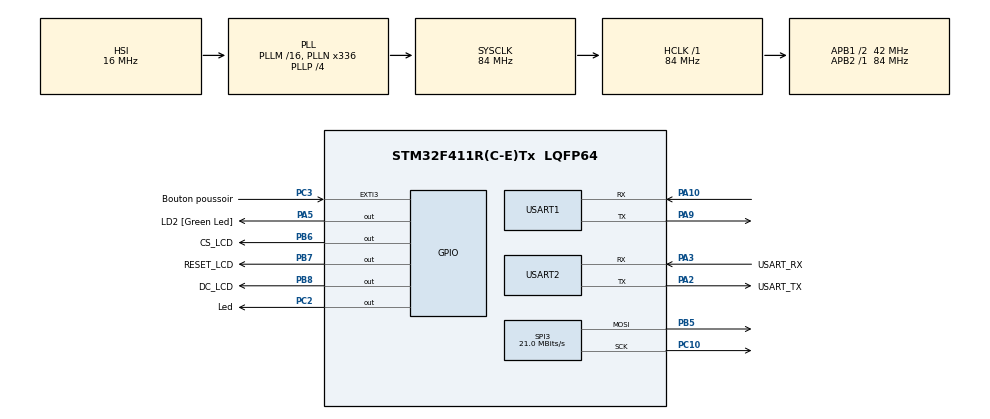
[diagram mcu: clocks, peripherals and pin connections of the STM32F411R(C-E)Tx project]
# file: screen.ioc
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Dma.Request0=SPI3_TX
Dma.SPI3_TX.0.Direction=DMA_MEMORY_TO_PERIPH
Dma.SPI3_TX.0.FIFOMode=DMA_FIFOMODE_DISABLE
Dma.SPI3_TX.0.Instance=DMA1_Stream5
Dma.SPI3_TX.0.MemDataAlignment=DMA_MDATAALIGN_BYTE
Dma.SPI3_TX.0.MemInc=DMA_MINC_ENABLE
Dma.SPI3_TX.0.Mode=DMA_NORMAL
Dma.SPI3_TX.0.PeriphDataAlignment=DMA_PDATAALIGN_BYTE
Dma.SPI3_TX.0.PeriphInc=DMA_PINC_DISABLE
Dma.SPI3_TX.0.Priority=DMA_PRIORITY_HIGH
Mcu.Family=STM32F4
Mcu.Name=STM32F411R(C-E)Tx
Mcu.Package=LQFP64
NVIC.DMA1_Stream5_IRQn=true\:0\:0\:false\:false\:true\:false\:true\:true
NVIC.EXTI3_IRQn=true\:0\:0\:false\:false\:true\:true\:true\:true
NVIC.PriorityGroup=NVIC_PRIORITYGROUP_0
PA10.Mode=Asynchronous
PA10.Signal=USART1_RX
PA13.GPIO_Label=TMS
PA13.Mode=Serial_Wire
PA13.Signal=SYS_JTMS-SWDIO
PA14.GPIO_Label=TCK
PA14.Mode=Serial_Wire
PA14.Signal=SYS_JTCK-SWCLK
PA2.GPIO_Label=USART_TX
PA2.Mode=Asynchronous
PA2.Signal=USART2_TX
PA3.GPIO_Label=USART_RX
PA3.Mode=Asynchronous
PA3.Signal=USART2_RX
PA5.GPIO_Label=LD2 [Green Led]
PA5.Signal=GPIO_Output
PA9.Mode=Asynchronous
PA9.Signal=USART1_TX
PB3.GPIO_Label=SWO
PB3.Signal=SYS_JTDO-SWO
PB5.Mode=TX_Only_Simplex_Unidirect_Master
PB5.Signal=SPI3_MOSI
PB6.GPIO_Label=CS_LCD
PB6.Signal=GPIO_Output
PB7.GPIO_Label=RESET_LCD
PB7.Signal=GPIO_Output
PB8.GPIO_Label=DC_LCD
PB8.Signal=GPIO_Output
PC10.Mode=TX_Only_Simplex_Unidirect_Master
PC10.Signal=SPI3_SCK
PC14-OSC32_IN.Mode=LSE-External-Oscillator
PC14-OSC32_IN.Signal=RCC_OSC32_IN
PC15-OSC32_OUT.Mode=LSE-External-Oscillator
PC15-OSC32_OUT.Signal=RCC_OSC32_OUT
PC2.GPIO_Label=Led
PC2.Signal=GPIO_Output
PC3.GPIO_Label=Bouton poussoir
PC3.GPIO_ModeDefaultEXTI=GPIO_MODE_IT_FALLING
PC3.GPIO_PuPd=GPIO_PULLUP
PC3.Signal=GPXTI3
PH0\ -\ OSC_IN.Mode=HSE-External-Clock-Source
PH0\ -\ OSC_IN.Signal=RCC_OSC_IN
PH1\ -\ OSC_OUT.Mode=HSE-External-Clock-Source
PH1\ -\ OSC_OUT.Signal=RCC_OSC_OUT
ProjectManager.HeapSize=0x200
ProjectManager.StackSize=0x400
ProjectManager.TargetToolchain=STM32CubeIDE
RCC.48MHZClocksFreq_Value=84000000
RCC.AHBFreq_Value=84000000
RCC.APB1CLKDivider=RCC_HCLK_DIV2
RCC.APB1Freq_Value=42000000
RCC.APB1TimFreq_Value=84000000
RCC.APB2Freq_Value=84000000
RCC.APB2TimFreq_Value=84000000
RCC.CortexFreq_Value=84000000
RCC.FLatency-AdvancedSettings=FLASH_LATENCY_2
RCC.HCLKFreq_Value=84000000
RCC.HSE_VALUE=8000000
RCC.HSI_VALUE=16000000
RCC.PLLN=336
RCC.PLLP=RCC_PLLP_DIV4
RCC.SYSCLKFreq_VALUE=84000000
RCC.SYSCLKSource=RCC_SYSCLKSOURCE_PLLCLK
RCC.VCOOutputFreq_Value=336000000
RTC.Format=RTC_FORMAT_BIN
RTC.Hours=10
RTC.Minutes=24
RTC.Seconds=45
SPI3.CalculateBaudRate=21.0 MBits/s
SPI3.Direction=SPI_DIRECTION_2LINES
SPI3.Mode=SPI_MODE_MASTER
SPI3.VirtualType=VM_MASTER
USART1.VirtualMode=VM_ASYNC
USART2.VirtualMode=VM_ASYNC
VP_RTC_VS_RTC_Activate.Mode=RTC_Enabled
VP_RTC_VS_RTC_Calendar.Mode=RTC_Calendar
board=NUCLEO-F411RE

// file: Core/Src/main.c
/* USER CODE BEGIN Header */
/**
  ******************************************************************************
  * @file           : main.c
  * @brief          : Main program body
  ******************************************************************************
  * @attention
  *
  * Copyright (c) 2024 STMicroelectronics.
  * All rights reserved.
  *
  * This software is licensed under terms that can be found in the LICENSE file
  * in the root directory of this software component.
  * If no LICENSE file comes with this software, it is provided AS-IS.
  *
  ******************************************************************************
  */
/* USER CODE END Header */
#include "main.h"

RTC_HandleTypeDef hrtc;

SPI_HandleTypeDef hspi3;
DMA_HandleTypeDef hdma_spi3_tx;

UART_HandleTypeDef huart1;
UART_HandleTypeDef huart2;

void SystemClock_Config(void);
static void MX_GPIO_Init(void);
static void MX_DMA_Init(void);
static void MX_USART2_UART_Init(void);
static void MX_SPI3_Init(void);
static void MX_RTC_Init(void);
static void MX_USART1_UART_Init(void);
/* USER CODE BEGIN PFP */
// Variable globale pour l'état de la LED
volatile uint8_t ledState = 0;

void HAL_GPIO_EXTI_Callback(uint16_t GPIO_Pin)
{
  if (GPIO_Pin == Bouton_poussoir_Pin)
  {
    ledState = !ledState;
    HAL_GPIO_WritePin(GPIOC, Led_Pin, ledState ? GPIO_PIN_SET : GPIO_PIN_RESET);
  }
}
/* USER CODE END PFP */

int main(void)
{

  /* MCU Configuration--------------------------------------------------------*/

  /* Reset of all peripherals, Initializes the Flash interface and the Systick. */
  HAL_Init();

  /* Configure the system clock */
  SystemClock_Config();

  /* Initialize all configured peripherals */
  MX_GPIO_Init();
  MX_DMA_Init();
  MX_USART2_UART_Init();
  MX_SPI3_Init();
  MX_RTC_Init();
  MX_USART1_UART_Init();

  /* Infinite loop */

    /* USER CODE BEGIN 3 */
  CLOCK_init();
  CLOCK_start();

  //CLOCK_start();

  /* USER CODE END 3 */
}

void SystemClock_Config(void)
{
  RCC_OscInitTypeDef RCC_OscInitStruct = {0};
  RCC_ClkInitTypeDef RCC_ClkInitStruct = {0};

  /** Configure the main internal regulator output voltage
  */
  __HAL_RCC_PWR_CLK_ENABLE();
  __HAL_PWR_VOLTAGESCALING_CONFIG(PWR_REGULATOR_VOLTAGE_SCALE1);

  /** Initializes the RCC Oscillators according to the specified parameters
  * in the RCC_OscInitTypeDef structure.
  */
  RCC_OscInitStruct.OscillatorType = RCC_OSCILLATORTYPE_HSI|RCC_OSCILLATORTYPE_LSI;
  RCC_OscInitStruct.HSIState = RCC_HSI_ON;
  RCC_OscInitStruct.HSICalibrationValue = RCC_HSICALIBRATION_DEFAULT;
  RCC_OscInitStruct.LSIState = RCC_LSI_ON;
  RCC_OscInitStruct.PLL.PLLState = RCC_PLL_ON;
  RCC_OscInitStruct.PLL.PLLSource = RCC_PLLSOURCE_HSI;
  RCC_OscInitStruct.PLL.PLLM = 16;
  RCC_OscInitStruct.PLL.PLLN = 336;
  RCC_OscInitStruct.PLL.PLLP = RCC_PLLP_DIV4;
  RCC_OscInitStruct.PLL.PLLQ = 4;
  if (HAL_RCC_OscConfig(&RCC_OscInitStruct) != HAL_OK)
  {
    Error_Handler();
  }

  /** Initializes the CPU, AHB and APB buses clocks
  */
  RCC_ClkInitStruct.ClockType = RCC_CLOCKTYPE_HCLK|RCC_CLOCKTYPE_SYSCLK
                              |RCC_CLOCKTYPE_PCLK1|RCC_CLOCKTYPE_PCLK2;
  RCC_ClkInitStruct.SYSCLKSource = RCC_SYSCLKSOURCE_PLLCLK;
  RCC_ClkInitStruct.AHBCLKDivider = RCC_SYSCLK_DIV1;
  RCC_ClkInitStruct.APB1CLKDivider = RCC_HCLK_DIV2;
  RCC_ClkInitStruct.APB2CLKDivider = RCC_HCLK_DIV1;

  if (HAL_RCC_ClockConfig(&RCC_ClkInitStruct, FLASH_LATENCY_2) != HAL_OK)
  {
    Error_Handler();
  }
}

static void MX_RTC_Init(void)
{

  RTC_TimeTypeDef sTime = {0};
  RTC_DateTypeDef sDate = {0};

  /** Initialize RTC Only
  */
  hrtc.Instance = RTC;
  hrtc.Init.HourFormat = RTC_HOURFORMAT_24;
  hrtc.Init.AsynchPrediv = 127;
  hrtc.Init.SynchPrediv = 255;
  hrtc.Init.OutPut = RTC_OUTPUT_DISABLE;
  hrtc.Init.OutPutPolarity = RTC_OUTPUT_POLARITY_HIGH;
  hrtc.Init.OutPutType = RTC_OUTPUT_TYPE_OPENDRAIN;
  if (HAL_RTC_Init(&hrtc) != HAL_OK)
  {
	Error_Handler();
  }

  /** Initialize RTC and set the Time and Date
  */
  sTime.Hours = 19;
  sTime.Minutes = 59;
  sTime.Seconds = 45;
  sTime.DayLightSaving = RTC_DAYLIGHTSAVING_NONE;
  sTime.StoreOperation = RTC_STOREOPERATION_RESET;
  if (HAL_RTC_SetTime(&hrtc, &sTime, RTC_FORMAT_BIN) != HAL_OK)
  {
	Error_Handler();
  }
  sDate.WeekDay = RTC_WEEKDAY_MONDAY;
  sDate.Month = RTC_MONTH_JANUARY;
  sDate.Date = 1;
  sDate.Year = 0;

  if (HAL_RTC_SetDate(&hrtc, &sDate, RTC_FORMAT_BIN) != HAL_OK)
  {
	Error_Handler();
  }
  /* USER CODE BEGIN RTC_Init 2 */
  HAL_NVIC_SetPriority(RTC_Alarm_IRQn, 0, 0);  // Priorité haute
  HAL_NVIC_EnableIRQ(RTC_Alarm_IRQn);
  /* USER CODE END RTC_Init 2 */

}

static void MX_SPI3_Init(void)
{

  /* SPI3 parameter configuration*/
  hspi3.Instance = SPI3;
  hspi3.Init.Mode = SPI_MODE_MASTER;
  hspi3.Init.Direction = SPI_DIRECTION_2LINES;
  hspi3.Init.DataSize = SPI_DATASIZE_8BIT;
  hspi3.Init.CLKPolarity = SPI_POLARITY_LOW;
  hspi3.Init.CLKPhase = SPI_PHASE_1EDGE;
  hspi3.Init.NSS = SPI_NSS_SOFT;
  hspi3.Init.BaudRatePrescaler = SPI_BAUDRATEPRESCALER_2;
  hspi3.Init.FirstBit = SPI_FIRSTBIT_MSB;
  hspi3.Init.TIMode = SPI_TIMODE_DISABLE;
  hspi3.Init.CRCCalculation = SPI_CRCCALCULATION_DISABLE;
  hspi3.Init.CRCPolynomial = 10;
  if (HAL_SPI_Init(&hspi3) != HAL_OK)
  {
    Error_Handler();
  }

}

static void MX_USART1_UART_Init(void)
{

  huart1.Instance = USART1;
  huart1.Init.BaudRate = 115200;
  huart1.Init.WordLength = UART_WORDLENGTH_8B;
  huart1.Init.StopBits = UART_STOPBITS_1;
  huart1.Init.Parity = UART_PARITY_NONE;
  huart1.Init.Mode = UART_MODE_TX_RX;
  huart1.Init.HwFlowCtl = UART_HWCONTROL_NONE;
  huart1.Init.OverSampling = UART_OVERSAMPLING_16;
  if (HAL_UART_Init(&huart1) != HAL_OK)
  {
    Error_Handler();
  }

}

static void MX_USART2_UART_Init(void)
{

  huart2.Instance = USART2;
  huart2.Init.BaudRate = 115200;
  huart2.Init.WordLength = UART_WORDLENGTH_8B;
  huart2.Init.StopBits = UART_STOPBITS_1;
  huart2.Init.Parity = UART_PARITY_NONE;
  huart2.Init.Mode = UART_MODE_TX_RX;
  huart2.Init.HwFlowCtl = UART_HWCONTROL_NONE;
  huart2.Init.OverSampling = UART_OVERSAMPLING_16;
  if (HAL_UART_Init(&huart2) != HAL_OK)
  {
    Error_Handler();
  }

}

static void MX_DMA_Init(void)
{

  /* DMA controller clock enable */
  __HAL_RCC_DMA1_CLK_ENABLE();

  /* DMA interrupt init */
  /* DMA1_Stream5_IRQn interrupt configuration */
  HAL_NVIC_SetPriority(DMA1_Stream5_IRQn, 0, 0);
  HAL_NVIC_EnableIRQ(DMA1_Stream5_IRQn);

}

static void MX_GPIO_Init(void)
{
  GPIO_InitTypeDef GPIO_InitStruct = {0};

  /* GPIO Ports Clock Enable */
  __HAL_RCC_GPIOC_CLK_ENABLE();
  __HAL_RCC_GPIOH_CLK_ENABLE();
  __HAL_RCC_GPIOA_CLK_ENABLE();
  __HAL_RCC_GPIOB_CLK_ENABLE();

  /*Configure GPIO pin Output Level */
  HAL_GPIO_WritePin(Led_GPIO_Port, Led_Pin, GPIO_PIN_RESET);

  /*Configure GPIO pin Output Level */
  HAL_GPIO_WritePin(LD2_GPIO_Port, LD2_Pin, GPIO_PIN_RESET);

  /*Configure GPIO pin Output Level */
  HAL_GPIO_WritePin(GPIOB, CS_LCD_Pin|RESET_LCD_Pin|DC_LCD_Pin, GPIO_PIN_RESET);

  /*Configure GPIO pin : Led_Pin */
  GPIO_InitStruct.Pin = Led_Pin;
  GPIO_InitStruct.Mode = GPIO_MODE_OUTPUT_PP;
  GPIO_InitStruct.Pull = GPIO_NOPULL;
  GPIO_InitStruct.Speed = GPIO_SPEED_FREQ_LOW;
  HAL_GPIO_Init(Led_GPIO_Port, &GPIO_InitStruct);

  /*Configure GPIO pin : Bouton_poussoir_Pin */
  GPIO_InitStruct.Pin = Bouton_poussoir_Pin;
  GPIO_InitStruct.Mode = GPIO_MODE_IT_FALLING;
  GPIO_InitStruct.Pull = GPIO_PULLUP;
  HAL_GPIO_Init(Bouton_poussoir_GPIO_Port, &GPIO_InitStruct);

  /*Configure GPIO pin : LD2_Pin */
  GPIO_InitStruct.Pin = LD2_Pin;
  GPIO_InitStruct.Mode = GPIO_MODE_OUTPUT_PP;
  GPIO_InitStruct.Pull = GPIO_NOPULL;
  GPIO_InitStruct.Speed = GPIO_SPEED_FREQ_LOW;
  HAL_GPIO_Init(LD2_GPIO_Port, &GPIO_InitStruct);

  /*Configure GPIO pins : CS_LCD_Pin RESET_LCD_Pin DC_LCD_Pin */
  GPIO_InitStruct.Pin = CS_LCD_Pin|RESET_LCD_Pin|DC_LCD_Pin;
  GPIO_InitStruct.Mode = GPIO_MODE_OUTPUT_PP;
  GPIO_InitStruct.Pull = GPIO_NOPULL;
  GPIO_InitStruct.Speed = GPIO_SPEED_FREQ_LOW;
  HAL_GPIO_Init(GPIOB, &GPIO_InitStruct);

  /* EXTI interrupt init*/
  HAL_NVIC_SetPriority(EXTI3_IRQn, 0, 0);
  HAL_NVIC_EnableIRQ(EXTI3_IRQn);

}

void Error_Handler(void)
{
  __disable_irq();
  while (1)
  {
  }
}
